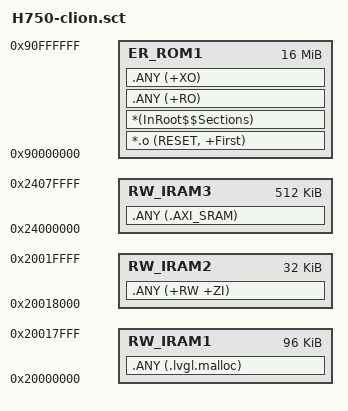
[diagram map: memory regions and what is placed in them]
LR_ROM1 0x90000000 0x01000000 {    ; ???????? LR_ROM1, ????? 0x90000000,??? 0x00800000 (8MB)
  ER_ROM1 0x90000000 0x01000000  {  ; ???????? ER_ROM1,???????????,???? 8MB
   *.o (RESET, +First)               ; ????????(.o)????RESET???,???????????????(+First ???????)
   *(InRoot$$Sections)               ; ??????? InRoot$$Sections ??
   .ANY (+RO)                        ; ???????(.RO)???????
   .ANY (+XO)                        ; ????????(.XO)???????
  }
  RW_IRAM1 0x20000000 0x00018000 {  ; 96KB 给 LVGL malloc
   .ANY (.lvgl.malloc)  ; LVGL 动态内存分配区域
}

RW_IRAM2 0x20018000 0x00008000 {  ; 剩余 32KB 用于其他任务
   .ANY (+RW +ZI)  ; 读写变量和零初始化数据
}
    RW_IRAM3 0x24000000 0x00080000  {  ; ????????? RW_IRAM2,????? 0x24000000,??? 0x00080000 (512KB)
   .ANY (.AXI_SRAM)                  ; ?????? .lvgl.dma ????????,????LVGL??DMA?????
  }
}

  ;ER_FLASH_WRITE 0x90200000 0x00600000 { 
  
      ;ER_ARRAY 0x90200000 0x00600000 {   
     ;.ANY (.ER_FLASH_WRITE)  
    ;        }
   ;} 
